# IOTKit_ARMv8MBLL register map
Vendor: ARM Ltd.; Series: ARMv8-M Baseline; File version: 1.0
CPU: ARMV8MBL r0p0, little endian, MPU, no FPU, 3 interrupt priority bits, 4 SAU regions
Registers are 32-bit, read-write, reset 0x0 unless marked. A register's access mark holds for its fields unless they carry their own. Offsets are from the block's base; [hi:lo] are bit positions; {n}, {i} and the like mark numbered series.

## GPIO0 — GPIO 0 (Non-Secure)
Base 0x40100000
Same registers: GPIO1 0x40101000, GPIO2 0x40102000, GPIO3 0x40103000, GPIO0_Secure 0x50100000, GPIO1_Secure 0x50101000, GPIO2_Secure 0x50102000, GPIO3_Secure 0x50103000
0x00 DATA
0x04 DATAOUT — Data Output Register
0x10 OUTENSET — Ouptut enable set Register
0x14 OUTENCLR — Ouptut enable clear Register
0x18 ALTFUNCSET — Alternate function set Register
0x1C ALTFUNCCLR — Alternate function clear Register
0x20 INTENSET — Interrupt enable set Register
0x24 INTENCLR — Interrupt enable clear Register
0x28 INTTYPESET — Interrupt type set Register
0x2C INTTYPECLR — Interrupt type clear Register
0x30 INTPOLSET — Polarity-level, edge interrupt configuration set Register
0x34 INTPOLCLR — Polarity-level, edge interrupt configuration clear Register
0x38 INTSTATUS ro — Interrupt Status Register
0x38 INTCLEAR wo write-1-clears (alternate view of INTSTATUS) — Interrupt CLEAR Register

## DMA0 — DMA 0 (Non-Secure)
Base 0x40110000
Same registers: DMA1 0x40111000, DMA2 0x40112000, DMA3 0x40113000, DMA0_SECURE 0x50110000, DMA1_SECURE 0x50111000, DMA2_SECURE 0x50112000, DMA3_SECURE 0x50113000
0x00 IntStatus — Interrupt Status Register
0x04 IntTCStatus ro — Interrupt Terminal Count Status Register
0x08 IntTCClear wo — Interrupt Terminal Count Clear Register
0x0C IntErrorStatus ro — Interrupt Error Status Register
0x10 IntErrClr wo — Interrupt Error Clear Register
0x14 RawIntTCStatus ro — Raw Interrupt Terminal Count Status Register
0x18 RawIntErrorStatus ro — Raw Error Interrupt Status Register
0x1C EnbldChns ro — Enabled Channel Register
0x20 SoftBReq — Software Burst Request Register
0x24 SoftSReq — Software Single Request Register
0x28 SoftLBReq — Software Last Burst Request Register
0x2C SoftLSReq — Software Last Single Request Register
0x30 Configuration
0x34 Sync — Synchronization Register
0x100 C0SrcAddr — Channel Source Address Registers
0x104 C0DestAddr — Channel Destination Address Registers
0x108 C0LLI — Channel Linked List Item Register
0x10C C0Control — Channel Control Registers
0x110 C0Configuration — Channel Configuration Registers
0x120 C1SrcAddr — Channel Source Address Registers
0x124 C1DestAddr — Channel Destination Address Registers
0x128 C1LLI — Channel Linked List Item Register
0x12C C1Control — Channel Control Registers
0x130 C1Configuration — Channel Configuration Registers
0x500 ITCR — Test Control Register
{0x500+4i} ITOP{i} (i=1..3) — Integration Test Output Register {i}

## SSP0 — SPI 0 (Non-Secure)
Base 0x40205000
Same registers: SSP1 0x40206000, SSP2 0x40209000, SSP3 0x4020A000, SSP4 0x4020B000, SSP0_Secure 0x50205000, SSP1_Secure 0x50206000, SSP2_Secure 0x50209000, SSP3_Secure 0x5020A000, SSP4_Secure 0x5020B000
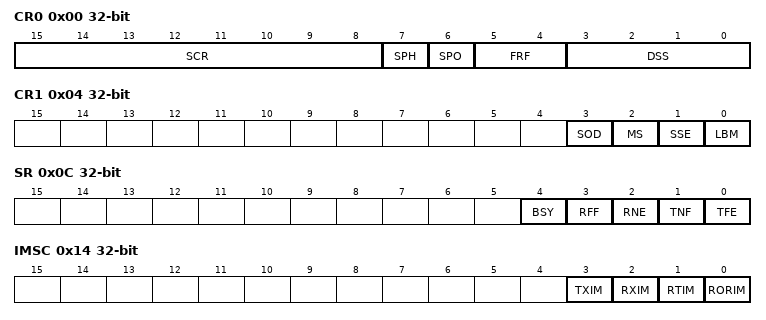
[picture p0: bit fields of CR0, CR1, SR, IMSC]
0x00 CR0 — Control register 0
  [15:8] SCR — Serial clock rate
  [7] SPH — SSPCLKOUT phase
  [6] SPO — SSPCLKOUT polarity
  [5:4] FRF — Frame format
  [3:0] DSS — Data Size Select
0x04 CR1 — Control register 1
  [3] SOD — Slave-mode output disable
  [2] MS — Master or slave mode select
  [1] SSE — Synchronous serial port enable
  [0] LBM — Loop back mode
0x08 DR — Data register
  [15:0] Data — Transmit/Receive FIFO
0x0C SR ro — Status register
  [4] BSY — PrimeCell SSP busy flag
  [3] RFF — Receive FIFO full
  [2] RNE — Receive FIFO not empty
  [1] TNF — Transmit FIFO not full
  [0] TFE — Transmit FIFO empty
0x10 CPSR — Clock prescale register
  [7:0] CPSDVSR — Clock prescale divisor
0x14 IMSC — Interrupt mask set or clear register
  [3] TXIM — Transmit FIFO interrupt mask
  [2] RXIM — Receive FIFO interrupt mask
  [1] RTIM — Receive timeout interrupt mask
  [0] RORIM — Receive overrun interrupt mask
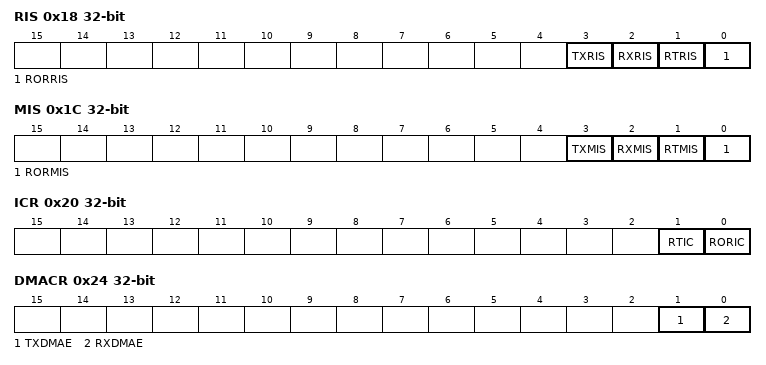
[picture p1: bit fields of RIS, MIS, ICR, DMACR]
0x18 RIS ro — Raw interrupt status register
  [3] TXRIS — transmit FIFOraw interrupt state
  [2] RXRIS — receive FIFO raw interrupt state
  [1] RTRIS — receive timeout raw interrupt state
  [0] RORRIS — receive over run raw interrupt state
0x1C MIS ro — Masked interrupt status register
  [3] TXMIS — transmit FIFO masked interrupt state
  [2] RXMIS — receive FIFO masked interrupt state
  [1] RTMIS — receive timeout masked interrupt state
  [0] RORMIS — receive over run masked interrupt state
0x20 ICR wo — Interrupt clear register
  [1] RTIC — Clears the SSPRTINTR interrupt
  [0] RORIC — Clears the SSPRORINTR interrupt
0x24 DMACR — DMA control register
  [1] TXDMAE — Transmit DMA Enable
  [0] RXDMAE — Receive DMA Enable
